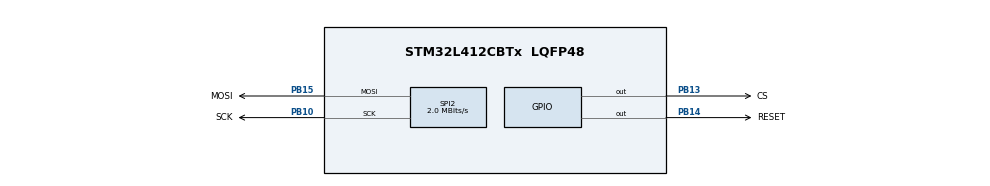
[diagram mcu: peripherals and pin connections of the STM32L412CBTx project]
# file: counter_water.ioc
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Mcu.Family=STM32L4
RCC.MSI_VALUE=4000000
SPI2.VirtualType=VM_MASTER
PB10.Mode=TX_Only_Simplex_Unidirect_Master
PB14.GPIO_Label=RESET
PB13.GPIO_Label=CS
PB15.Signal=SPI2_MOSI
PB13.Signal=GPIO_Output
ProjectManager.StackSize=0x400
ProjectManager.TargetToolchain=STM32CubeIDE
PB10.GPIO_Label=SCK
RCC.USBFreq_Value=4000000
RCC.LSE_VALUE=32768
PB10.Signal=SPI2_SCK
PB14.Signal=GPIO_Output
RCC.HSE_VALUE=8000000
board=custom
RCC.VCOOutputFreq_Value=32000000
PB15.Mode=TX_Only_Simplex_Unidirect_Master
PB15.GPIO_Label=MOSI
RCC.ADCFreq_Value=4000000
SPI2.CalculateBaudRate=2.0 MBits/s
Mcu.Name=STM32L412CBTx
Mcu.Package=LQFP48
SPI2.Mode=SPI_MODE_MASTER
ProjectManager.HeapSize=0x200
RCC.HSI_VALUE=16000000
NVIC.PriorityGroup=NVIC_PRIORITYGROUP_4
SPI2.DataSize=SPI_DATASIZE_9BIT
SPI2.Direction=SPI_DIRECTION_2LINES
RCC.HSI48_VALUE=48000000

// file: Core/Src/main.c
/* USER CODE BEGIN Header */
/**
  ******************************************************************************
  * @file           : main.c
  * @brief          : Main program body
  ******************************************************************************
  * @attention
  *
  * <h2><center>&copy; Copyright (c) 2021 STMicroelectronics.
  * All rights reserved.</center></h2>
  *
  * This software component is licensed by ST under BSD 3-Clause license,
  * the "License"; You may not use this file except in compliance with the
  * License. You may obtain a copy of the License at:
  *                        opensource.org/licenses/BSD-3-Clause
  *
  ******************************************************************************
  */
/* USER CODE END Header */
#include "main.h"

SPI_HandleTypeDef hspi2;

void SystemClock_Config(void);
static void MX_GPIO_Init(void);
static void MX_SPI2_Init(void);

/* USER CODE BEGIN 0 */
#include "n1202.h"

/* USER CODE END 0 */

int main(void)
{

  /* MCU Configuration--------------------------------------------------------*/

  /* Reset of all peripherals, Initializes the Flash interface and the Systick. */
  HAL_Init();

  /* Configure the system clock */
  SystemClock_Config();

  /* Initialize all configured peripherals */
  MX_GPIO_Init();
  MX_SPI2_Init();
  /* USER CODE BEGIN 2 */
  LCD_Init(&hspi2);
  HAL_Delay(500);
  /* USER CODE END 2 */

  /* Infinite loop */
  while (1)
  {

    /* USER CODE BEGIN 3 */
	  LCD_testBigFont(&hspi2);
  }
  /* USER CODE END 3 */
}

void SystemClock_Config(void)
{
  RCC_OscInitTypeDef RCC_OscInitStruct = {0};
  RCC_ClkInitTypeDef RCC_ClkInitStruct = {0};

  /** Configure the main internal regulator output voltage
  */
  if (HAL_PWREx_ControlVoltageScaling(PWR_REGULATOR_VOLTAGE_SCALE1) != HAL_OK)
  {
    Error_Handler();
  }
  /** Initializes the RCC Oscillators according to the specified parameters
  * in the RCC_OscInitTypeDef structure.
  */
  RCC_OscInitStruct.OscillatorType = RCC_OSCILLATORTYPE_MSI;
  RCC_OscInitStruct.MSIState = RCC_MSI_ON;
  RCC_OscInitStruct.MSICalibrationValue = 0;
  RCC_OscInitStruct.MSIClockRange = RCC_MSIRANGE_6;
  RCC_OscInitStruct.PLL.PLLState = RCC_PLL_NONE;
  if (HAL_RCC_OscConfig(&RCC_OscInitStruct) != HAL_OK)
  {
    Error_Handler();
  }
  /** Initializes the CPU, AHB and APB buses clocks
  */
  RCC_ClkInitStruct.ClockType = RCC_CLOCKTYPE_HCLK|RCC_CLOCKTYPE_SYSCLK
                              |RCC_CLOCKTYPE_PCLK1|RCC_CLOCKTYPE_PCLK2;
  RCC_ClkInitStruct.SYSCLKSource = RCC_SYSCLKSOURCE_MSI;
  RCC_ClkInitStruct.AHBCLKDivider = RCC_SYSCLK_DIV1;
  RCC_ClkInitStruct.APB1CLKDivider = RCC_HCLK_DIV1;
  RCC_ClkInitStruct.APB2CLKDivider = RCC_HCLK_DIV1;

  if (HAL_RCC_ClockConfig(&RCC_ClkInitStruct, FLASH_LATENCY_0) != HAL_OK)
  {
    Error_Handler();
  }
}

static void MX_SPI2_Init(void)
{

  /* SPI2 parameter configuration*/
  hspi2.Instance = SPI2;
  hspi2.Init.Mode = SPI_MODE_MASTER;
  hspi2.Init.Direction = SPI_DIRECTION_2LINES;
  hspi2.Init.DataSize = SPI_DATASIZE_9BIT;
  hspi2.Init.CLKPolarity = SPI_POLARITY_LOW;
  hspi2.Init.CLKPhase = SPI_PHASE_1EDGE;
  hspi2.Init.NSS = SPI_NSS_SOFT;
  hspi2.Init.BaudRatePrescaler = SPI_BAUDRATEPRESCALER_2;
  hspi2.Init.FirstBit = SPI_FIRSTBIT_MSB;
  hspi2.Init.TIMode = SPI_TIMODE_DISABLE;
  hspi2.Init.CRCCalculation = SPI_CRCCALCULATION_DISABLE;
  hspi2.Init.CRCPolynomial = 7;
  hspi2.Init.CRCLength = SPI_CRC_LENGTH_DATASIZE;
  hspi2.Init.NSSPMode = SPI_NSS_PULSE_ENABLE;
  if (HAL_SPI_Init(&hspi2) != HAL_OK)
  {
    Error_Handler();
  }

}

static void MX_GPIO_Init(void)
{
  GPIO_InitTypeDef GPIO_InitStruct = {0};

  /* GPIO Ports Clock Enable */
  __HAL_RCC_GPIOB_CLK_ENABLE();

  /*Configure GPIO pin Output Level */
  HAL_GPIO_WritePin(GPIOB, CS_Pin|RESET_Pin, GPIO_PIN_RESET);

  /*Configure GPIO pins : CS_Pin RESET_Pin */
  GPIO_InitStruct.Pin = CS_Pin|RESET_Pin;
  GPIO_InitStruct.Mode = GPIO_MODE_OUTPUT_PP;
  GPIO_InitStruct.Pull = GPIO_NOPULL;
  GPIO_InitStruct.Speed = GPIO_SPEED_FREQ_LOW;
  HAL_GPIO_Init(GPIOB, &GPIO_InitStruct);

}

void Error_Handler(void)
{
  __disable_irq();
  while (1)
  {
  }
}

/************************ (C) COPYRIGHT STMicroelectronics *****END OF FILE****/
